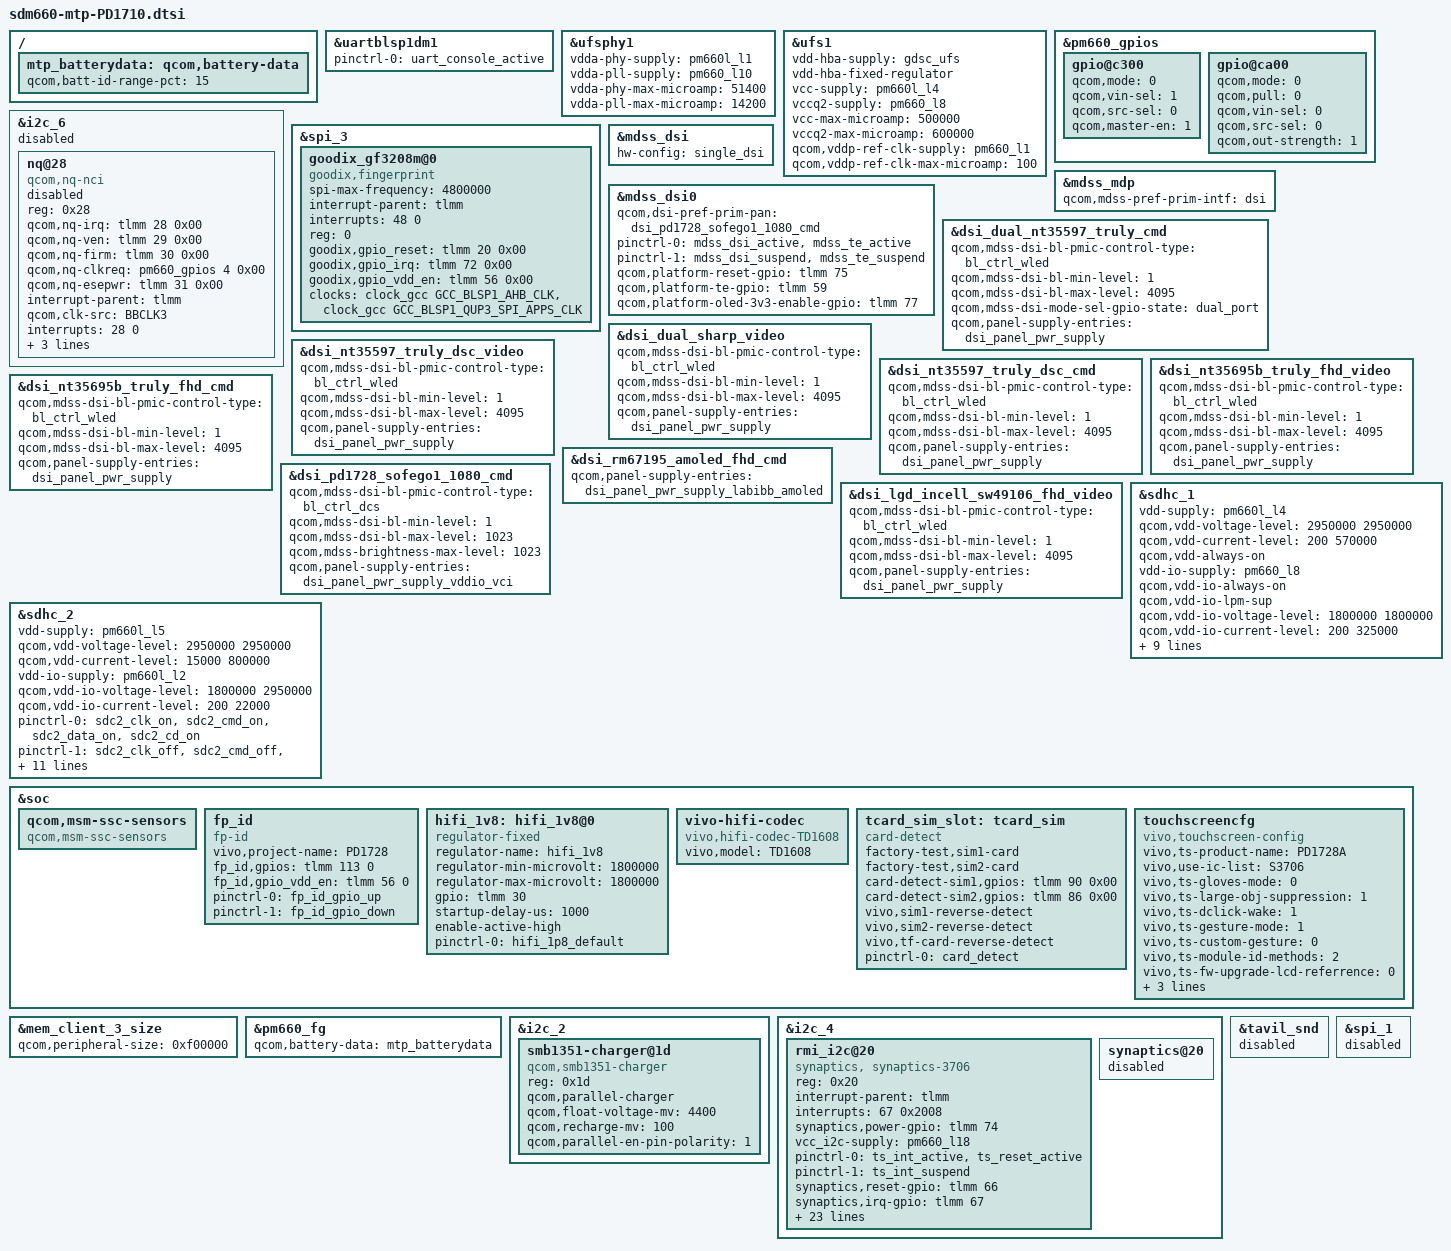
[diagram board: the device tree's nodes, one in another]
/* Copyright (c) 2016-2018, The Linux Foundation. All rights reserved.
 *
 * This program is free software; you can redistribute it and/or modify
 * it under the terms of the GNU General Public License version 2 and
 * only version 2 as published by the Free Software Foundation.
 *
 * This program is distributed in the hope that it will be useful,
 * but WITHOUT ANY WARRANTY; without even the implied warranty of
 * MERCHANTABILITY or FITNESS FOR A PARTICULAR PURPOSE.  See the
 * GNU General Public License for more details.
 */

#include "sdm660-pinctrl-PD1710.dtsi"
#include "sdm660-camera-sensor-mtp.dtsi"
/ {
	mtp_batterydata: qcom,battery-data {
		qcom,batt-id-range-pct = <15>;
		#include "fg-gen3-batterydata-itech-3000mah.dtsi"
		#include "fg-gen3-batterydata-ascent-3450mah.dtsi"
	};
};

&uartblsp1dm1 {
	status = "ok";
	pinctrl-names = "default";
	pinctrl-0 = <&uart_console_active>;
};

&ufsphy1 {
	vdda-phy-supply = <&pm660l_l1>;
	vdda-pll-supply = <&pm660_l10>;
	vdda-phy-max-microamp = <51400>;
	vdda-pll-max-microamp = <14200>;
	status = "ok";
};

&ufs1 {
	vdd-hba-supply = <&gdsc_ufs>;
	vdd-hba-fixed-regulator;
	vcc-supply = <&pm660l_l4>;
	vccq2-supply = <&pm660_l8>;
	vcc-max-microamp = <500000>;
	vccq2-max-microamp = <600000>;
	qcom,vddp-ref-clk-supply = <&pm660_l1>;
	qcom,vddp-ref-clk-max-microamp = <100>;

	status = "ok";
};

&pm660_gpios {
	/* GPIO 4 (NFC_CLK_REQ) */
	gpio@c300 {
		qcom,mode = <0>;
		qcom,vin-sel = <1>;
		qcom,src-sel = <0>;
		qcom,master-en = <1>;
		status = "okay";
	};

	/* GPIO 11 for Home Key */
	gpio@ca00 {
		status = "okay";
		qcom,mode = <0>;
		qcom,pull = <0>;
		qcom,vin-sel = <0>;
		qcom,src-sel = <0>;
		qcom,out-strength = <1>;
	};
};

&i2c_6 { /* BLSP1 QUP6 (NFC) */
	status = "disabled";
	nq@28 {
		status = "disabled";
		compatible = "qcom,nq-nci";
		reg = <0x28>;
		qcom,nq-irq = <&tlmm 28 0x00>;
		qcom,nq-ven = <&tlmm 29 0x00>;
		qcom,nq-firm = <&tlmm 30 0x00>;
		qcom,nq-clkreq = <&pm660_gpios 4 0x00>;
		qcom,nq-esepwr = <&tlmm 31 0x00>;
		interrupt-parent = <&tlmm>;
		qcom,clk-src = "BBCLK3";
		interrupts = <28 0>;
		interrupt-names = "nfc_irq";
		pinctrl-names = "nfc_active", "nfc_suspend";
		pinctrl-0 = <&nfc_int_active &nfc_enable_active>;
		pinctrl-1 = <&nfc_int_suspend &nfc_enable_suspend>;
		clocks = <&clock_rpmcc RPM_LN_BB_CLK3_PIN>;
		clock-names = "ref_clk";
	};
};

/* zhangguang add for fingerprint start */
&spi_3  {
	status = "ok";
	
    goodix_gf3208m@0 {
	compatible = "goodix,fingerprint";
	spi-max-frequency = <4800000>;
	interrupt-parent = <&tlmm>;
	interrupts = <48 0>;
	reg = <0>;
	
	goodix,gpio_reset = <&tlmm 20 0x00>;
	goodix,gpio_irq = <&tlmm 72 0x00>;
	goodix,gpio_vdd_en= <&tlmm 56 0x00>;
	
	clock-names = "iface_clk", "core_clk";
	clocks = <&clock_gcc GCC_BLSP1_AHB_CLK>,
			<&clock_gcc GCC_BLSP1_QUP3_SPI_APPS_CLK>;
    };
};
/* zhangguang add for fingerprint end */

&mdss_mdp {
	qcom,mdss-pref-prim-intf = "dsi";
};

&mdss_dsi {
	hw-config = "single_dsi";
};

&mdss_dsi0 {
	qcom,dsi-pref-prim-pan = <&dsi_pd1728_sofego1_1080_cmd>;
	pinctrl-names = "mdss_default", "mdss_sleep";
	pinctrl-0 = <&mdss_dsi_active &mdss_te_active>;
	pinctrl-1 = <&mdss_dsi_suspend &mdss_te_suspend>;
	qcom,platform-reset-gpio = <&tlmm 75 0>;
	qcom,platform-te-gpio = <&tlmm 59 0>;
	//qcom,platform-enable-gpio = <&tlmm 77 0>;
	qcom,platform-oled-3v3-enable-gpio = <&tlmm 77 0>;
};

/*&mdss_dsi1 {
	qcom,dsi-pref-prim-pan = <&dsi_dual_nt35597_truly_video>;
	pinctrl-names = "mdss_default", "mdss_sleep";
	pinctrl-0 = <&mdss_dsi_active &mdss_te_active>;
	pinctrl-1 = <&mdss_dsi_suspend &mdss_te_suspend>;
	qcom,platform-reset-gpio = <&tlmm 53 0>;
	qcom,platform-te-gpio = <&tlmm 59 0>;
};

&mdss_dp_ctrl {
	pinctrl-names = "mdss_dp_active", "mdss_dp_sleep";
	pinctrl-0 = <&mdss_dp_aux_active &mdss_dp_usbplug_cc_active>;
	pinctrl-1 = <&mdss_dp_aux_suspend &mdss_dp_usbplug_cc_suspend>;
	qcom,aux-en-gpio = <&tlmm 55 0>;
	qcom,aux-sel-gpio = <&tlmm 56 0>;
	qcom,usbplug-cc-gpio = <&tlmm 58 0>;
};

&pm660l_wled {
	qcom,led-strings-list = [01 02];
};*/


&dsi_dual_nt35597_truly_cmd {
	qcom,mdss-dsi-bl-pmic-control-type = "bl_ctrl_wled";
	qcom,mdss-dsi-bl-min-level = <1>;
	qcom,mdss-dsi-bl-max-level = <4095>;
	qcom,mdss-dsi-mode-sel-gpio-state = "dual_port";
	qcom,panel-supply-entries = <&dsi_panel_pwr_supply>;
};

&dsi_dual_sharp_video {
	qcom,mdss-dsi-bl-pmic-control-type = "bl_ctrl_wled";
	qcom,mdss-dsi-bl-min-level = <1>;
	qcom,mdss-dsi-bl-max-level = <4095>;
	qcom,panel-supply-entries = <&dsi_panel_pwr_supply>;
};

&dsi_nt35597_truly_dsc_video {
	qcom,mdss-dsi-bl-pmic-control-type = "bl_ctrl_wled";
	qcom,mdss-dsi-bl-min-level = <1>;
	qcom,mdss-dsi-bl-max-level = <4095>;
	qcom,panel-supply-entries = <&dsi_panel_pwr_supply>;
};

&dsi_nt35597_truly_dsc_cmd {
	qcom,mdss-dsi-bl-pmic-control-type = "bl_ctrl_wled";
	qcom,mdss-dsi-bl-min-level = <1>;
	qcom,mdss-dsi-bl-max-level = <4095>;
	qcom,panel-supply-entries = <&dsi_panel_pwr_supply>;
};

&dsi_nt35695b_truly_fhd_video {
	qcom,mdss-dsi-bl-pmic-control-type = "bl_ctrl_wled";
	qcom,mdss-dsi-bl-min-level = <1>;
	qcom,mdss-dsi-bl-max-level = <4095>;
	qcom,panel-supply-entries = <&dsi_panel_pwr_supply>;
};

&dsi_nt35695b_truly_fhd_cmd {
	qcom,mdss-dsi-bl-pmic-control-type = "bl_ctrl_wled";
	qcom,mdss-dsi-bl-min-level = <1>;
	qcom,mdss-dsi-bl-max-level = <4095>;
	qcom,panel-supply-entries = <&dsi_panel_pwr_supply>;
};

&dsi_rm67195_amoled_fhd_cmd {
	qcom,panel-supply-entries = <&dsi_panel_pwr_supply_labibb_amoled>;
};

&dsi_lgd_incell_sw49106_fhd_video {
	qcom,mdss-dsi-bl-pmic-control-type = "bl_ctrl_wled";
	qcom,mdss-dsi-bl-min-level = <1>;
	qcom,mdss-dsi-bl-max-level = <4095>;
	qcom,panel-supply-entries = <&dsi_panel_pwr_supply>;
};

&dsi_pd1728_sofego1_1080_cmd {
	qcom,mdss-dsi-bl-pmic-control-type = "bl_ctrl_dcs";
	qcom,mdss-dsi-bl-min-level = <1>;
	qcom,mdss-dsi-bl-max-level = <1023>;
	qcom,mdss-brightness-max-level = <1023>;
	qcom,panel-supply-entries = <&dsi_panel_pwr_supply_vddio_vci>;
};

&sdhc_1 {
	/* device core power supply */
	vdd-supply = <&pm660l_l4>;
	qcom,vdd-voltage-level = <2950000 2950000>;
	qcom,vdd-current-level = <200 570000>;
	qcom,vdd-always-on;

	/* device communication power supply */
	vdd-io-supply = <&pm660_l8>;
	qcom,vdd-io-always-on;
	qcom,vdd-io-lpm-sup;
	qcom,vdd-io-voltage-level = <1800000 1800000>;
	qcom,vdd-io-current-level = <200 325000>;

	pinctrl-names = "active", "sleep";
	pinctrl-0 = <&sdc1_clk_on &sdc1_cmd_on &sdc1_data_on &sdc1_rclk_on>;
	pinctrl-1 = <&sdc1_clk_off &sdc1_cmd_off &sdc1_data_off &sdc1_rclk_off>;

	qcom,clk-rates = <400000 20000000 25000000 50000000 100000000 192000000
								384000000>;

	qcom,nonremovable;
	qcom,bus-speed-mode = "HS400_1p8v", "HS200_1p8v", "DDR_1p8v";

	status = "ok";
};

&sdhc_2 {
	/* device core power supply */
	vdd-supply = <&pm660l_l5>;
	qcom,vdd-voltage-level = <2950000 2950000>;
	qcom,vdd-current-level = <15000 800000>;

	/* device communication power supply */
	vdd-io-supply = <&pm660l_l2>;
	qcom,vdd-io-voltage-level = <1800000 2950000>;
	qcom,vdd-io-current-level = <200 22000>;

	pinctrl-names = "active", "sleep";
	pinctrl-0 = <&sdc2_clk_on &sdc2_cmd_on &sdc2_data_on &sdc2_cd_on>;
	pinctrl-1 = <&sdc2_clk_off &sdc2_cmd_off &sdc2_data_off &sdc2_cd_off>;

	#address-cells = <0>;
	interrupt-parent = <&sdhc_2>;
	interrupts = <0 1 2>;
	#interrupt-cells = <1>;
	interrupt-map-mask = <0xffffffff>;
	interrupt-map = <0 &intc 0 0 125 0
			1 &intc 0 0 221 0
			2 &tlmm 54 0>;
	interrupt-names = "hc_irq", "pwr_irq", "status_irq";
	cd-gpios = <&tlmm 54 0x0>;

	qcom,clk-rates = <400000 20000000 25000000 50000000 100000000
							/*	200000000 */ >;
	qcom,bus-speed-mode = "SDR12", "SDR25", "SDR50", "DDR50", "SDR104";

	status = "ok";
};

&soc {
	qcom,msm-ssc-sensors {
		compatible = "qcom,msm-ssc-sensors";
	};

	/* zhangguang add for fingerprint start */
	fp_id:fp_id {
		compatible = "fp-id";
		status = "ok";
		vivo,project-name = "PD1728";
		fp_id,gpios = <&tlmm 113 0>;
		fp_id,gpio_vdd_en = <&tlmm 56 0>;
		pinctrl-names = "fp_id_gpio_up",
						"fp_id_gpio_down";
		pinctrl-0 = <&fp_id_gpio_up>;
		pinctrl-1 = <&fp_id_gpio_down>;
	};
	/* zhangguang add for fingerprint end */

	hifi_1v8: hifi_1v8@0 {
		compatible = "regulator-fixed";
		regulator-name = "hifi_1v8";
		regulator-min-microvolt = <1800000>;
		regulator-max-microvolt = <1800000>;
		gpio = <&tlmm 30 0>;
		startup-delay-us = <1000>;
		enable-active-high;
		pinctrl-names = "default";
		pinctrl-0 = <&hifi_1p8_default>;
	};

	vivo-hifi-codec {
		compatible = "vivo,hifi-codec-TD1608";
		vivo,model = "TD1608";
	};

	/*xuling added for sim detect*/
	tcard_sim_slot:tcard_sim {
		status = "ok";
		compatible = "card-detect";
		factory-test,sim1-card;
		factory-test,sim2-card;
		card-detect-sim1,gpios = <&tlmm 90 0x00>;
		card-detect-sim2,gpios = <&tlmm 86 0x00>;
		vivo,sim1-reverse-detect;
		vivo,sim2-reverse-detect;
		vivo,tf-card-reverse-detect;
		pinctrl-names = "default";
		pinctrl-0 = <&card_detect>;
	};
	/*xuling added for sim detect end*/
};

&mem_client_3_size {
	qcom,peripheral-size = <0xf00000>;
};

&pm660_fg {
	qcom,battery-data = <&mtp_batterydata>;
};

&i2c_2 {
	status = "ok";
	smb1351-charger@1d {
		compatible = "qcom,smb1351-charger";
		reg = <0x1d>;
		qcom,parallel-charger;
		qcom,float-voltage-mv = <4400>;
		qcom,recharge-mv = <100>;
		qcom,parallel-en-pin-polarity = <1>;
	};
};
/**zhaik_add*/
&i2c_4 { /* BLSP1 QUP4 */
	status = "ok";	/* after this platform,must enable iic bus */
	rmi_i2c@20 {
		compatible = "synaptics, synaptics-3706";
		reg = <0x20>;
		interrupt-parent = <&tlmm>;
		interrupts = <67 0x2008>;
		synaptics,power-gpio = <&tlmm 74 0x00>;
		vcc_i2c-supply = <&pm660_l18>;

		/* pins used by touchscreen */
		//pinctrl-names ="default";
		//pinctrl-0 = <&ts_reset_active>;
		
		pinctrl-names = "ts_int_active","ts_int_suspend";
		pinctrl-0 = <&ts_int_active &ts_reset_active>;
		pinctrl-1 = <&ts_int_suspend>;
		
		synaptics,reset-gpio = <&tlmm 66 0x00>; 
		synaptics,irq-gpio = <&tlmm 67 0x00>;
		synaptics,attn_polarity = <0x02>;
		
		udg-reg-control=<0x67>;
		udg-reg-signature-write=<0x6a>;
            
		ts-dimension-by-lcm=<1>;
		ts-suspend-resume=<0>;

		lcd-dimension-x=<1080>;
		lcd-dimension-y=<2280>;

		ts-dimension-x=<1080>;
		ts-dimension-y=<2280>;

		ts-dclick-trip-x-area=<140>;
		ts-dclick-trip-y-area=<200>;
		ts-dclick-two-fingers-x-area=<200>;
		ts-dclick-two-fingers-y-area=<190>;			
		   
		ts-fixed-key-type=<0>; /*0=0d,1=2d */
		/*--virtualkeys: EV_KEY:KEY_MENU:cx:cy:w:h:EV_KEY:KEY_HOMEPAGE:cx:cy:w:h:EV_KEY:KEY_BACK:cx:cy:w:h--*/
		ts-virt-key="0x01:139:117:1345:130:100:0x01:172:360:1345:140:100:0x01:158:603:1345:130:100";
		

		
		//add for 3706
		synaptics,irq-on-state = <0>;
		synaptics,reset-on-state = <0>;
		synaptics,power-delay-ms = <200>;
		synaptics,reset-delay-ms = <100>;
		synaptics,reset-active-ms = <20>;
		synaptics,ub-i2c-addr = <0x2c>;
		synaptics,power-on-state = <1>;
	};
	synaptics@20 {
		status = "disabled";
	};
};

&soc {
	touchscreencfg { /* vivo ts configure */
	   compatible = "vivo,touchscreen-config";
	   vivo,ts-product-name="PD1728A";
	   vivo,use-ic-list="S3706";
	   
	   /*----- function set BEG ---- */
	   vivo,ts-gloves-mode=<0>;
	   vivo,ts-large-obj-suppression=<1>;
	   vivo,ts-dclick-wake=<1>;
	   vivo,ts-gesture-mode=<1>; /*1=sold in native,2=sold in abroad,3...etc=for custom extensive*/
	   vivo,ts-custom-gesture=<0>;
	   vivo,ts-module-id-methods=<2>;/*0=by IC id,1=gpio,2=by LCD ID 3=...etc=for custom extensive*/
	   vivo,ts-fw-upgrade-lcd-referrence=<0>;
	   vivo,ts-anti-esd=<1>;
	   vivo,ts-charger-conn-judge=<1>;
	   vivo,ts-module-smt-mode=<1>; /* 0=COB,1=COF */
	   /*----- function set END ---- */

       /* for FW upgrade HW ID check */
	   /*vivo,ts-module-id1-gpio=<0>;*/
	   /*vivo,ts-module-id2-gpio=<3>;*/
	   //vivo,ts-module-id1-gpio=  <&msm_gpio 0 0x0>;
	   //vivo,ts-module-id2-gpio = <&msm_gpio 3 0x0>;
	   
	    /* id pins used by touchscreen */
		//pinctrl-names = "ts_id_active","ts_id_disactive";
		//pinctrl-0 = <&ts_id_active>;
		//pinctrl-1 = <&ts_id_disactive>;

	};
};

&tavil_snd {
	status = "disabled";
};

&spi_1 {
	status = "disabled";
};
